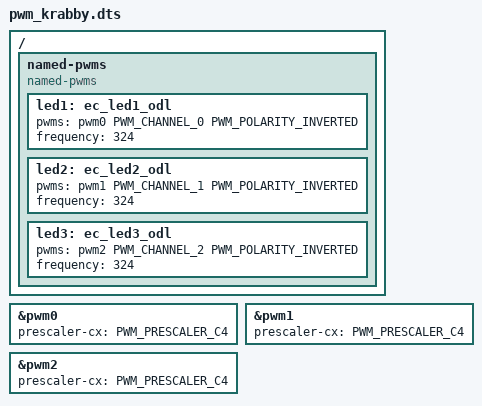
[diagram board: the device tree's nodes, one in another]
/* Copyright 2021 The Chromium OS Authors. All rights reserved.
 * Use of this source code is governed by a BSD-style license that can be
 * found in the LICENSE file.
 */

/ {
	named-pwms {
		compatible = "named-pwms";
		/* NOTE: &pwm number needs same with channel number */
		led1: ec_led1_odl {
			#pwm-cells = <0>;
			pwms = <&pwm0 PWM_CHANNEL_0 PWM_POLARITY_INVERTED>;
			/*
			 * If we need pwm output in ITE chip power saving
			 * mode, then we should set frequency <=324Hz.
			 */
			frequency = <324>;
		};
		led2: ec_led2_odl {
			#pwm-cells = <0>;
			pwms = <&pwm1 PWM_CHANNEL_1 PWM_POLARITY_INVERTED>;
			frequency = <324>;
		};
		led3: ec_led3_odl {
			#pwm-cells = <0>;
			pwms = <&pwm2 PWM_CHANNEL_2 PWM_POLARITY_INVERTED>;
			frequency = <324>;
		};
	};
};

/* LED1 */
&pwm0 {
	status = "okay";
	prescaler-cx = <PWM_PRESCALER_C4>;
};

/* LED2 */
&pwm1 {
	status = "okay";
	prescaler-cx = <PWM_PRESCALER_C4>;
};

/* LED3 */
&pwm2 {
	status = "okay";
	prescaler-cx = <PWM_PRESCALER_C4>;
};
